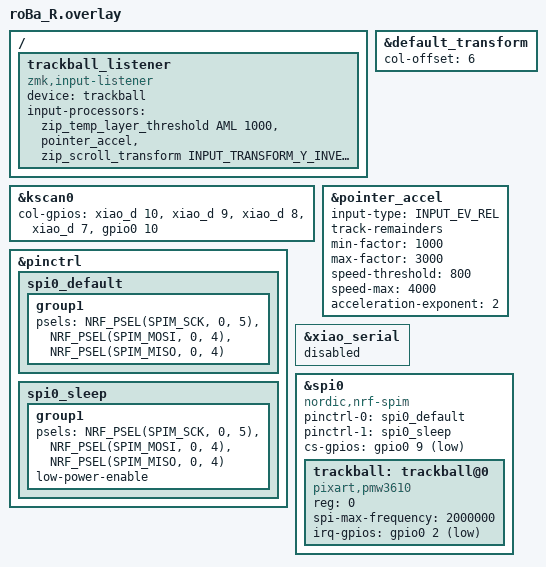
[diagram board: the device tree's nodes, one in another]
#include "roBa.dtsi"
#include <input/processors.dtsi>
#include <behaviors/input_gestures_accel.dtsi>
#include <dt-bindings/zmk/input_transform.h>

&default_transform {
    col-offset = <6>;
};

#define AML 4  // Your AML layer index / AMLレイヤーのインデックス

&kscan0 {
        col-gpios
            = <&xiao_d 10 GPIO_ACTIVE_HIGH>
            , <&xiao_d 9 GPIO_ACTIVE_HIGH>
            , <&xiao_d 8 GPIO_ACTIVE_HIGH>
            , <&xiao_d 7 GPIO_ACTIVE_HIGH>
            , <&gpio0 10 GPIO_ACTIVE_HIGH>
            ;
};

&pointer_accel {
    input-type = <INPUT_EV_REL>;
    track-remainders;
    min-factor = <1000>;
    max-factor = <3000>;
    speed-threshold = <800>;
    speed-max = <4000>;
    acceleration-exponent = <2>;
};

// &zip_temp_layer {
//     require-prior-idle-ms = <200>;
// };

// / {
//     trackball_listener {
//         status = "okay";
//         compatible = "zmk,input-listener";
//         device = <&trackball>;
//         input-processors = <&zip_temp_layer 4 1000 &pointer_accel &zip_scroll_transform INPUT_TRANSFORM_Y_INVERT>;
//         // input-processors = <&zip_temp_layer 4 900 &zip_scroll_transform INPUT_TRANSFORM_Y_INVERT>;
//     };
// };

/ {
    trackball_listener {
    status = "okay";
    compatible = "zmk,input-listener";
    device = <&trackball>;
    
    // <layer_index timeout_ms>
    // input-processors = <&zip_temp_layer_threshold AML 30000>;
    input-processors = <&zip_temp_layer_threshold AML 1000 &pointer_accel &zip_scroll_transform INPUT_TRANSFORM_Y_INVERT>;
    };
};

&pinctrl {
    spi0_default: spi0_default {
        group1 {
            psels = <NRF_PSEL(SPIM_SCK, 0, 5)>,
                <NRF_PSEL(SPIM_MOSI, 0, 4)>,
                <NRF_PSEL(SPIM_MISO, 0, 4)>;
        };
    };

    spi0_sleep: spi0_sleep {
        group1 {
            psels = <NRF_PSEL(SPIM_SCK, 0, 5)>,
                <NRF_PSEL(SPIM_MOSI, 0, 4)>,
                <NRF_PSEL(SPIM_MISO, 0, 4)>;
            low-power-enable;
        };
    };
};

&xiao_serial { status = "disabled"; };

&spi0 {
    status = "okay";
    compatible = "nordic,nrf-spim";
    pinctrl-0 = <&spi0_default>;
    pinctrl-1 = <&spi0_sleep>;
    pinctrl-names = "default", "sleep";
    cs-gpios = <&gpio0 9 GPIO_ACTIVE_LOW>;

    trackball: trackball@0 {
        status = "okay";
        compatible = "pixart,pmw3610";
        reg = <0>;
        spi-max-frequency = <2000000>;
        irq-gpios = <&gpio0 2 (GPIO_ACTIVE_LOW | GPIO_PULL_UP)>;
    };
};
